AUTOSAR XML (schema 00048)
package /AUTOLIV/SoftwareComponents/PAL
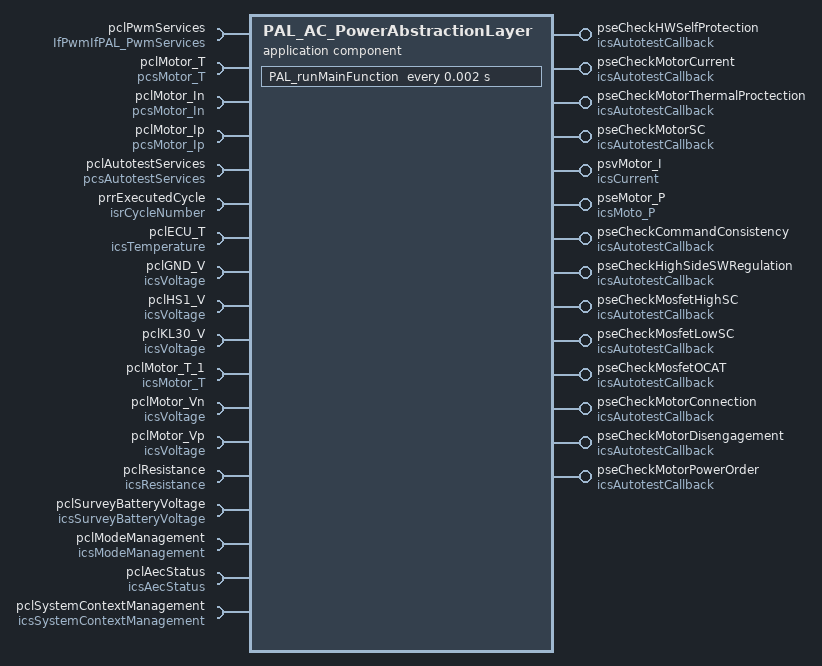
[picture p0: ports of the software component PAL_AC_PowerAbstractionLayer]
  application sw component type PAL_AC_PowerAbstractionLayer
    require port pclPwmServices: required-com-specs=[SetDutyCycle, EnablePWM, DisablePWM], required-interface=IfPwmIfPAL_PwmServices
    4 x provide port, all with server-com-spec{operation=AutotestCallback, queue-length=1}, provided-interface=icsAutotestCallback:
      pseCheckHWSelfProtection
      pseCheckMotorCurrent
      pseCheckMotorThermalProctection
      pseCheckMotorSC
    require port pclMotor_T: required-com-specs=[GetDeficiencyLevel, InitializeDeficiencyLevel], required-interface=pcsMotor_T
    provide port psvMotor_I: provided-interface=icsCurrent
      provided-com-specs:
        operation=Get_mA, queue-length=1
        operation=Get_LSB, queue-length=1
        operation=Get_A, queue-length=1
        operation=ConvertCurrent_mAtoLSB, queue-length=1
    require port pclMotor_In: required-com-specs=[raw_Get_10ms, raw_Get], required-interface=pcsMotor_In
    require port pclMotor_Ip: required-com-specs=[raw_Get_10ms, raw_Get], required-interface=pcsMotor_Ip
    provide port pseMotor_P: provided-com-specs=[{operation=SetPowerOrder, queue-length=1}, {operation=GetPowerOrder, queue-length=1}], provided-interface=icsMoto_P
    12 x require port:
      pclAutotestServices: client-com-spec=GetTestResult, required-interface=pcsAutotestServices
      prrExecutedCycle: nonqueued-receiver-com-spec{data-element=u8CycleNumber, init-value=constant-reference=APPLINIT_KU8_CYCLE_NUMBER_NONE}, required-interface=isrCycleNumber
      pclECU_T: required-com-specs=[GetFiltered, GetFiltered_deg, Init], required-interface=icsTemperature
      pclGND_V: required-com-specs=[Get, Get_100ms, Get_10ms, Get_20ms, Get_2ms], required-interface=icsVoltage
      pclHS1_V: required-com-specs=[Get, Get_100ms, Get_10ms, Get_20ms, Get_2ms], required-interface=icsVoltage
      pclKL30_V: required-com-specs=[Get, Get_100ms, Get_10ms, Get_20ms, Get_2ms], required-interface=icsVoltage
      pclMotor_T_1: required-com-specs=[GetDeficiencyLevel, InitializeDeficiencyLevel], required-interface=icsMotor_T
      pclMotor_Vn: required-com-specs=[Get, Get_100ms, Get_10ms, Get_20ms, Get_2ms], required-interface=icsVoltage
      pclMotor_Vp: required-com-specs=[Get, Get_100ms, Get_10ms, Get_20ms, Get_2ms], required-interface=icsVoltage
      pclResistance: client-com-spec=Get, required-interface=icsResistance
      pclSurveyBatteryVoltage: required-com-specs=[GetStatus, Monitor], required-interface=icsSurveyBatteryVoltage
      pclModeManagement: client-com-spec=CheckModeStatus, required-interface=icsModeManagement
    8 x provide port, all with server-com-spec{operation=AutotestCallback, queue-length=1}, provided-interface=icsAutotestCallback:
      pseCheckCommandConsistency
      pseCheckHighSideSWRegulation
      pseCheckMosfetHighSC
      pseCheckMosfetLowSC
      pseCheckMosfetOCAT
      pseCheckMotorConnection
      pseCheckMotorDisengagement
      pseCheckMotorPowerOrder
    require port pclAecStatus: required-interface=icsAecStatus
      required-com-specs:
        SetAecEvent
        GetNumberOfImplementedAec
        GetAecStatus
        GetAecQualificationCount
        GetAecNvpBlockRecordingStatus
        GetAecGroupsStatus
        GetAecDeskillThrs
    require port pclSystemContextManagement: required-interface=icsSystemContextManagement
      required-com-specs:
        SuperviseKL30bg
        RestoreSystemContext
        ManageSystemContextStorage
        GetMonitoredCycle
        GetLastTensionningState
        GetBatteryHysteresisThrs
    behavior PAL_AC_PowerAbstractionLayer_InternalBehavior: data-type-mapping=DataTypeMappingSet_PP4G
      init event PAL_AC_PowerAbstractionLayer_InitEvent: start-on-event=PAL_Init
      timing event TMT_PAL_runMainFunction: start-on-event=PAL_runMainFunction, period=0.002
      16 x operation invoked event:
        OIT_PAL_runReadMotorCurrentInmA_psvMotor_I_Get_mA: start-on-event=PAL_runReadMotorCurrentInmA, operation=psvMotor_I.Get_mA
        OIT_PAL_runReadMotorCurrentInA_psvMotor_I_Get_A: start-on-event=PAL_runReadMotorCurrentInA, operation=psvMotor_I.Get_A
        OIT_PAL_runSetPowerOrder_pseMotor_P_SetPowerOrder: start-on-event=PAL_runSetPowerOrder, operation=pseMotor_P.SetPowerOrder
        OIT_PAL_runGetPWMOrder_pseMotor_P_GetPowerOrder: start-on-event=PAL_runGetPWMOrder, operation=pseMotor_P.GetPowerOrder
        OIT_PAL_Autotest_CheckCommandConsistency_pseCheckCommandConsistency_AutotestCallback: start-on-event=PAL_Autotest_CheckCommandConsistency, operation=pseCheckCommandConsistency.AutotestCallback
        OIT_PAL_Autotest_CheckMosfetLowSC_psecheckMosfetLowSC_AutotestCallback: start-on-event=PAL_Autotest_CheckMosfetLowSC, operation=pseCheckMosfetLowSC.AutotestCallback
        OIT_PAL_Autotest_CheckMosfetHighSC_pseCheckMosfetHighSC_AutotestCallback: start-on-event=PAL_Autotest_CheckMosfetHighSC, operation=pseCheckMosfetHighSC.AutotestCallback
        OIT_PAL_Autotest_CheckMosfetOCAT_pseCheckMosfetOCAT_AutotestCallback: start-on-event=PAL_Autotest_CheckMosfetOCAT, operation=pseCheckMosfetOCAT.AutotestCallback
        OIT_PAL_Autotest_CheckHighSideSwRegulation_pseCheckHighSideSWRegulation_AutotestCallback: start-on-event=PAL_Autotest_CheckHighSideSwRegulation, operation=pseCheckHighSideSWRegulation.AutotestCallback
        OIT_PAL_Autotest_CheckMotorConnection_pseMotorConnection_AutotestCallback: start-on-event=PAL_Autotest_CheckMotorConnection, operation=pseCheckMotorConnection.AutotestCallback
        OIT_PAL_Autotest_CheckMotorPowerOrder_pseMotorPowerOrder_AutotestCallback: start-on-event=PAL_Autotest_CheckMotorPowerOrder, operation=pseCheckMotorPowerOrder.AutotestCallback
        OIT_PAL_Autotest_CheckMotorDisengagement_pseMotorDisengagement_AutotestCallback: start-on-event=PAL_Autotest_CheckMotorDisengagement, operation=pseCheckMotorDisengagement.AutotestCallback
        OIT_PAL_Autotest_CheckMotorSC_pseCheckMotorSC_AutotestCallback: start-on-event=PAL_Autotest_CheckMotorSC, operation=pseCheckMotorSC.AutotestCallback
        OIT_PAL_Autotest_CheckMotorThermalProctection_pseCheckMotorThermalProctection_AutotestCallback: start-on-event=PAL_Autotest_CheckMotorThermalProctection, operation=pseCheckMotorThermalProctection.AutotestCallback
        OIT_PAL_Autotest_CheckMotorCurrent_pseCheckMotorCurrent_AutotestCallback: start-on-event=PAL_Autotest_CheckMotorCurrent, operation=pseCheckMotorCurrent.AutotestCallback
        OIT_PAL_Autotest_CheckHWSelfProtection_pseCheckHWSelfProtection_AutotestCallback: start-on-event=PAL_Autotest_CheckHWSelfProtection, operation=pseCheckHWSelfProtection.AutotestCallback
      explicit-inter-runnable-variables:
        4 x data, all with init-value=0:
          bModeStatus: type=u8ModeStatusType
          u8CycleNumber: type=u8CycleNumberType
          u8EventStatusExtended: type=Dem_EventStatusExtendedType
          u8AutoTestId: type=u8AutoTestIdType
      18 x runnable:
        PAL_Init
        PAL_runMainFunction
          18 x sync call:
            SC_pclPwmServices_DisablePWM: operation=pclPwmServices.DisablePWM
            SC_pclPwmServices_EnablePWM: operation=pclPwmServices.EnablePWM
            SC_pclPwmServices_SetDutyCycle: operation=pclPwmServices.SetDutyCycle
            SC_pclHS1_V_Get: operation=pclHS1_V.Get
            SC_pclKL30_V_Get_100ms: operation=pclKL30_V.Get_100ms
            SC_pclGND_V_Get_100ms: operation=pclGND_V.Get_100ms
            SC_pclMotor_Vp_Get_100ms: operation=pclMotor_Vp.Get_100ms
            SC_pclMotor_Vn_Get_100ms: operation=pclMotor_Vn.Get_100ms
            SC_pclKL30_V_Get_20ms: operation=pclKL30_V.Get_20ms
            SC_pclGND_V_Get_20ms: operation=pclGND_V.Get_20ms
            SC_pclMotor_Vp_Get_20ms: operation=pclMotor_Vp.Get_20ms
            SC_pclMotor_Vn_Get_20ms: operation=pclMotor_Vn.Get_20ms
            SC_pclSurveyBatteryVoltage_GetStatus: operation=pclSurveyBatteryVoltage.GetStatus
            SC_pclModeManagement_CheckModeStatus: operation=pclModeManagement.CheckModeStatus
            SC_pclECU_T_GetFiltered_deg: operation=pclECU_T.GetFiltered_deg
            SC_pclKL30_V_Get_10ms: operation=pclKL30_V.Get_10ms
            SC_pclResistance_Get: operation=pclResistance.Get
            SC_pclAecStatus_GetAecStatus: operation=pclAecStatus.GetAecStatus
        PAL_Autotest_CheckMotorCurrent
          data-receive-point-by-arguments:
            access REC_prrExecutedCycle_u8CycleNumber: accessed-variable=prrExecutedCycle.u8CycleNumber
          sync call SC_pclMotor_In_raw_Get: operation=pclMotor_In.raw_Get
          sync call SC_pclMotor_Ip_raw_Get: operation=pclMotor_Ip.raw_Get
          sync call SC_pclAutotestServices_GetTestResult: operation=pclAutotestServices.GetTestResult
        PAL_Autotest_CheckHWSelfProtection
          sync call SC_pclMotor_In_raw_Get_10ms: operation=pclMotor_In.raw_Get_10ms
          sync call SC_pclMotor_Ip_raw_Get_10ms: operation=pclMotor_Ip.raw_Get_10ms
          sync call SC_pclAutotestServices_GetTestResult: operation=pclAutotestServices.GetTestResult
        PAL_Autotest_CheckMotorThermalProctection
          sync call SC_pclMotor_T_GetDeficiencyLevel: operation=pclMotor_T.GetDeficiencyLevel
          sync call SC_pclAutotestServices_GetTestResult: operation=pclAutotestServices.GetTestResult
        PAL_runReadMotorCurrentInA: can-be-invoked-concurrently=true
        PAL_runSetPowerOrder: can-be-invoked-concurrently=true
        PAL_runReadMotorCurrentInmA: can-be-invoked-concurrently=true
        PAL_runGetPWMOrder: can-be-invoked-concurrently=true
        PAL_Autotest_CheckCommandConsistency
        PAL_Autotest_CheckMosfetLowSC
        PAL_Autotest_CheckMosfetHighSC
        PAL_Autotest_CheckMosfetOCAT
        PAL_Autotest_CheckHighSideSwRegulation
          sync call SC_pclSystemContextManagement_GetLastTensionningState: operation=pclSystemContextManagement.GetLastTensionningState
        PAL_Autotest_CheckMotorConnection
        PAL_Autotest_CheckMotorPowerOrder
        PAL_Autotest_CheckMotorDisengagement
        PAL_Autotest_CheckMotorSC
  swc implementation PAL_AC_PowerAbstractionLayer_Implementation: behavior=PAL_AC_PowerAbstractionLayer_InternalBehavior
